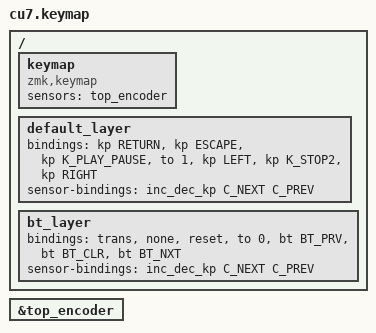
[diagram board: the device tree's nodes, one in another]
/*
 * Copyright (c) 2020 The ZMK Contributors
 *
 * SPDX-License-Identifier: MIT
 */

#include <behaviors.dtsi>
#include <dt-bindings/zmk/keys.h>
#include <dt-bindings/zmk/bt.h>
#include <dt-bindings/zmk/reset.h>

&top_encoder {
    status = "okay";
};

/ {
  keymap {
    compatible = "zmk,keymap";
    sensors = <&top_encoder>;
  };

    default_layer {
      bindings = <
        &kp RETURN &kp ESCAPE &kp K_PLAY_PAUSE &to 1 &kp LEFT &kp K_STOP2 &kp RIGHT 
      >;
      sensor-bindings = <&inc_dec_kp C_NEXT C_PREV>;
    };

    bt_layer {
      bindings = <
        &trans &none &reset &to 0 &bt BT_PRV &bt BT_CLR &bt BT_NXT 
      >;
      sensor-bindings = <&inc_dec_kp C_NEXT C_PREV>;
    };

};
